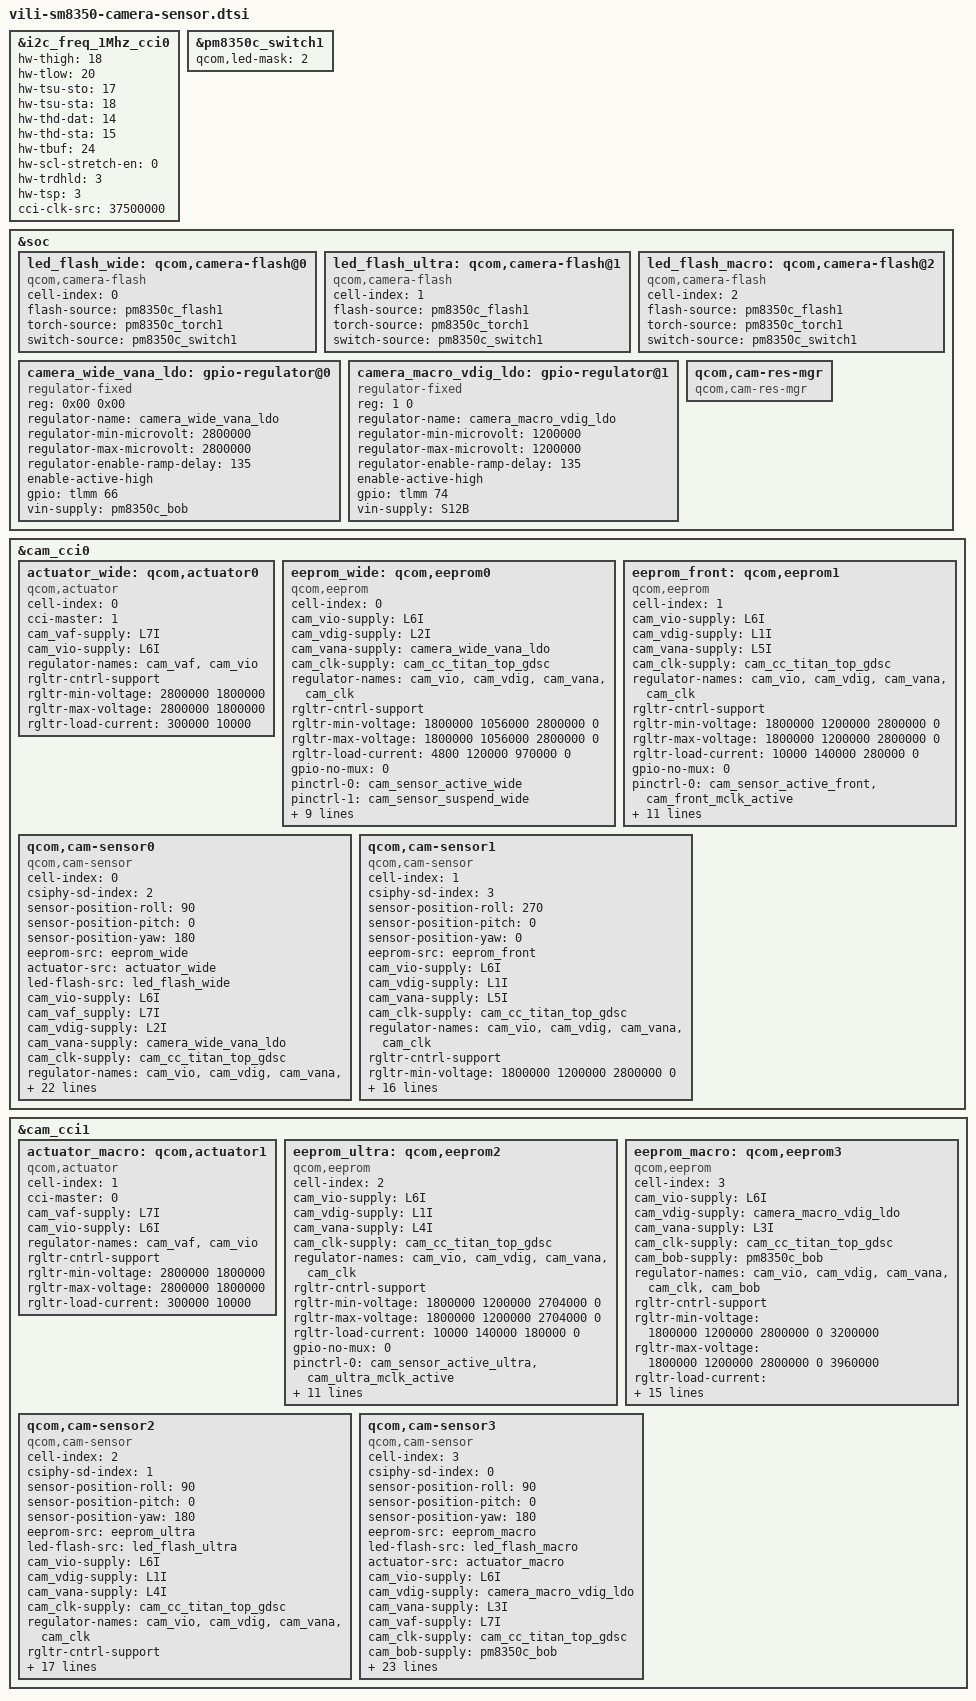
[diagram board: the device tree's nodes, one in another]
#include <dt-bindings/clock/qcom,camcc-lahaina.h>

&i2c_freq_1Mhz_cci0 {
	hw-thigh = <18>;
	hw-tlow = <20>;
	hw-tsu-sto = <17>;
	hw-tsu-sta = <18>;
	hw-thd-dat = <14>;
	hw-thd-sta = <15>;
	hw-tbuf = <24>;
	hw-scl-stretch-en = <0>;
	hw-trdhld = <3>;
	hw-tsp = <3>;
	cci-clk-src = <37500000>;
	status = "ok";
};

&pm8350c_switch1 {
	qcom,led-mask = <2>; /* Channels 2*/
};

&soc {
	led_flash_wide: qcom,camera-flash@0 {
		cell-index = <0>;
		compatible = "qcom,camera-flash";
		flash-source = <&pm8350c_flash1>;
		torch-source = <&pm8350c_torch1>;
		switch-source = <&pm8350c_switch1>;
		status = "ok";
	};

	led_flash_ultra: qcom,camera-flash@1 {
		cell-index = <1>;
		compatible = "qcom,camera-flash";
		flash-source = <&pm8350c_flash1>;
		torch-source = <&pm8350c_torch1>;
		switch-source = <&pm8350c_switch1>;
		status = "ok";
	};

	led_flash_macro: qcom,camera-flash@2 {
		cell-index = <2>;
		compatible = "qcom,camera-flash";
		flash-source = <&pm8350c_flash1>;
		torch-source = <&pm8350c_torch1>;
		switch-source = <&pm8350c_switch1>;
		status = "ok";
	};

	camera_wide_vana_ldo: gpio-regulator@0 {
		compatible = "regulator-fixed";
		reg = <0x00 0x00>;
		regulator-name = "camera_wide_vana_ldo";
		regulator-min-microvolt = <2800000>;
		regulator-max-microvolt = <2800000>;
		regulator-enable-ramp-delay = <135>;
		enable-active-high;
		gpio = <&tlmm 66 0>;
                vin-supply = <&pm8350c_bob>;
	};

	camera_macro_vdig_ldo: gpio-regulator@1 {
		compatible = "regulator-fixed";
		reg = <1 0>;
		regulator-name = "camera_macro_vdig_ldo";
		regulator-min-microvolt = <1200000>;
		regulator-max-microvolt = <1200000>;
		regulator-enable-ramp-delay = <135>;
		enable-active-high;
		gpio = <&tlmm 74 0>;
		vin-supply = <&S12B>;
	};

	qcom,cam-res-mgr {
		compatible = "qcom,cam-res-mgr";
	};
};

&cam_cci0 {
        actuator_wide: qcom,actuator0 {
                cell-index = <0>;
                compatible = "qcom,actuator";
                cci-master = <1>;
                cam_vaf-supply = <&L7I>;
                cam_vio-supply = <&L6I>;
                regulator-names = "cam_vaf", "cam_vio";
                rgltr-cntrl-support;
                rgltr-min-voltage = <2800000 1800000>;
                rgltr-max-voltage = <2800000 1800000>;
                rgltr-load-current = <300000 10000>;
                status = "ok";
        };

	eeprom_wide: qcom,eeprom0 {
		cell-index = <0>;
		compatible = "qcom,eeprom";
		cam_vio-supply = <&L6I>;
		cam_vdig-supply = <&L2I>;
		cam_vana-supply = <&camera_wide_vana_ldo>;
		cam_clk-supply = <&cam_cc_titan_top_gdsc>;
		regulator-names = "cam_vio", "cam_vdig", "cam_vana", "cam_clk";
		rgltr-cntrl-support;
		rgltr-min-voltage = <1800000 1056000 2800000 0>;
		rgltr-max-voltage = <1800000 1056000 2800000 0>;
		rgltr-load-current = <4800 120000 970000 0>;
		gpio-no-mux = <0>;
		pinctrl-names = "cam_default", "cam_suspend";
		pinctrl-0 = <&cam_sensor_active_wide>;
		pinctrl-1 = <&cam_sensor_suspend_wide>;
		gpios = <&tlmm 101 0>,
			<&tlmm 16 0>;
		gpio-reset = <1>;
		gpio-req-tbl-num = <0 1>;
		gpio-req-tbl-flags = <1 0>;
		gpio-req-tbl-label = "CAMIF_MCLK1",
					"CAM_RESET1";
		cci-master = <1>;
		clocks = <&clock_camcc CAM_CC_MCLK1_CLK>;
		clock-names = "cam_clk";
		clock-cntl-level = "nominal";
		clock-rates = <19200000>;
		status = "ok";
	};

	eeprom_front: qcom,eeprom1 {
		cell-index = <1>;
		compatible = "qcom,eeprom";
		cam_vio-supply = <&L6I>;
		cam_vdig-supply = <&L1I>;
		cam_vana-supply = <&L5I>;
		cam_clk-supply = <&cam_cc_titan_top_gdsc>;
		regulator-names = "cam_vio", "cam_vdig", "cam_vana", "cam_clk";
		rgltr-cntrl-support;
		rgltr-min-voltage = <1800000 1200000 2800000 0>;
		rgltr-max-voltage = <1800000 1200000 2800000 0>;
		rgltr-load-current = <10000 140000 280000 0>;
		gpio-no-mux = <0>;
		pinctrl-names = "cam_default", "cam_suspend";
		pinctrl-0 = <&cam_sensor_active_front
			&cam_front_mclk_active>;
		pinctrl-1 = <&cam_sensor_suspend_front
			&cam_front_mclk_suspend>;
		gpios = <&tlmm 100 0>,
			<&tlmm 17 0>;
		gpio-reset = <1>;
		gpio-req-tbl-num = <0 1>;
		gpio-req-tbl-flags = <1 0>;
		gpio-req-tbl-label = "CAMIF_MCLK0",
					"CAM_RESET0";
		cci-master = <0>;
		clocks = <&clock_camcc CAM_CC_MCLK0_CLK>;
		clock-names = "cam_clk";
		clock-cntl-level = "nominal";
		clock-rates = <19200000>;
		status = "ok";
	};

	// wide IMX686 64M AVDD 2.8V
	// wide S5KHM2 108M AVDD 2.9V
	qcom,cam-sensor0 {
		cell-index = <0>;
		compatible = "qcom,cam-sensor";
		csiphy-sd-index = <2>;
		sensor-position-roll = <90>;
		sensor-position-pitch = <0>;
		sensor-position-yaw = <180>;
		eeprom-src = <&eeprom_wide>;
		actuator-src = <&actuator_wide>;
		led-flash-src = <&led_flash_wide>;
		cam_vio-supply = <&L6I>;
		cam_vaf_supply = <&L7I>;
		cam_vdig-supply = <&L2I>;
		cam_vana-supply = <&camera_wide_vana_ldo>;
		cam_clk-supply = <&cam_cc_titan_top_gdsc>;
		regulator-names = "cam_vio", "cam_vdig", "cam_vana", "cam_vaf", "cam_clk";
		rgltr-cntrl-support;
		rgltr-min-voltage = <1800000 1056000 2800000 2800000 0>;
		rgltr-max-voltage = <1800000 1056000 2800000 2800000 0>;
		rgltr-load-current = <10000 140000 280000 280000 0>;
		gpio-no-mux = <0>;
                pinctrl-names = "cam_default", "cam_suspend";
                pinctrl-0 = <&cam_wide_mclk_active
                        &cam_sensor_active_wide>;
                pinctrl-1 = <&cam_wide_mclk_suspend
                        &cam_sensor_suspend_wide>;
		gpios = <&tlmm 101 0>,
			<&tlmm 16 0>;
		gpio-reset = <1>;
		gpio-req-tbl-num = <0 1>;
		gpio-req-tbl-flags = <1 0>;
		gpio-req-tbl-label = "CAMIF_MCLK1",
					"CAM_RESET1";
		cci-master = <1>;
		clocks = <&clock_camcc CAM_CC_MCLK1_CLK>;
		clock-names = "cam_clk";
		clock-cntl-level = "nominal";
		clock-rates = <19200000>;
		status = "ok";
	};

	// Front 20M
	qcom,cam-sensor1 {
		cell-index = <1>;
		compatible = "qcom,cam-sensor";
		csiphy-sd-index = <3>;
		sensor-position-roll = <270>;
		sensor-position-pitch = <0>;
		sensor-position-yaw = <0>;
		eeprom-src = <&eeprom_front>;
		cam_vio-supply = <&L6I>;
		cam_vdig-supply = <&L1I>;
		cam_vana-supply = <&L5I>;
		cam_clk-supply = <&cam_cc_titan_top_gdsc>;
		regulator-names = "cam_vio", "cam_vdig", "cam_vana", "cam_clk";
		rgltr-cntrl-support;
		rgltr-min-voltage = <1800000 1200000 2800000 0>;
		rgltr-max-voltage = <1800000 1200000 2800000 0>;
		rgltr-load-current = <10000 140000 280000 0>;
		gpio-no-mux = <0>;
		pinctrl-names = "cam_default", "cam_suspend";
		pinctrl-0 = <&cam_sensor_active_front
			&cam_front_mclk_active>;
		pinctrl-1 = <&cam_sensor_suspend_front
			&cam_front_mclk_suspend>;
		gpios = <&tlmm 100 0>,
			<&tlmm 17 0>;
		gpio-reset = <1>;
		gpio-req-tbl-num = <0 1>;
		gpio-req-tbl-flags = <1 0>;
		gpio-req-tbl-label = "CAMIF_MCLK0",
					"CAM_RESET0";
		cci-master = <0>;
		clocks = <&clock_camcc CAM_CC_MCLK0_CLK>;
		clock-names = "cam_clk";
		clock-cntl-level = "nominal";
		clock-rates = <19200000>;
		status = "ok";
	};

};

&cam_cci1 {
        actuator_macro: qcom,actuator1 {
                cell-index = <1>;
                compatible = "qcom,actuator";
                cci-master = <0>;
                cam_vaf-supply = <&L7I>;
                cam_vio-supply = <&L6I>;
                regulator-names = "cam_vaf", "cam_vio";
                rgltr-cntrl-support;
                rgltr-min-voltage = <2800000 1800000>;
                rgltr-max-voltage = <2800000 1800000>;
                rgltr-load-current = <300000 10000>;
                status = "ok";
        };

	eeprom_ultra: qcom,eeprom2 {
		cell-index = <2>;
		compatible = "qcom,eeprom";
		cam_vio-supply = <&L6I>;
		cam_vdig-supply = <&L1I>;
		cam_vana-supply = <&L4I>;
		cam_clk-supply = <&cam_cc_titan_top_gdsc>;
		regulator-names = "cam_vio", "cam_vdig", "cam_vana", "cam_clk";
		rgltr-cntrl-support;
		rgltr-min-voltage = <1800000 1200000 2704000 0>;
		rgltr-max-voltage = <1800000 1200000 2704000 0>;
		rgltr-load-current = <10000 140000 180000 0>;
		gpio-no-mux = <0>;
		pinctrl-names = "cam_default", "cam_suspend";
		pinctrl-0 = <&cam_sensor_active_ultra
				&cam_ultra_mclk_active>;
		pinctrl-1 = <&cam_sensor_suspend_ultra
				&cam_ultra_mclk_suspend>;
		gpios = <&tlmm 103 0>,
			<&tlmm 117 0>;
		gpio-reset = <1>;
		gpio-req-tbl-num = <0 1>;
		gpio-req-tbl-flags = <1 0>;
		gpio-req-tbl-label = "CAMIF_MCLK3",
					"CAM_RESET3";
		cci-master = <1>;
		clocks = <&clock_camcc CAM_CC_MCLK3_CLK>;
		clock-names = "cam_clk";
		clock-cntl-level = "nominal";
		clock-rates = <19200000>;
		status = "ok";
	};

	eeprom_macro: qcom,eeprom3 {
		cell-index = <3>;
		compatible = "qcom,eeprom";
		cam_vio-supply = <&L6I>;
		cam_vdig-supply = <&camera_macro_vdig_ldo>;
		cam_vana-supply = <&L3I>;
		cam_clk-supply = <&cam_cc_titan_top_gdsc>;
		cam_bob-supply = <&pm8350c_bob>;
		regulator-names = "cam_vio", "cam_vdig", "cam_vana"
			          , "cam_clk", "cam_bob";
		rgltr-cntrl-support;
		rgltr-min-voltage = <1800000 1200000 2800000 0 3200000>;
		rgltr-max-voltage = <1800000 1200000 2800000 0 3960000>;
		rgltr-load-current = <10000 140000 180000 0 2000000>;
		gpio-no-mux = <0>;
		pinctrl-names = "cam_default", "cam_suspend";
		pinctrl-0 = <&cam_sensor_active_macro
				&cam_macro_mclk_active>;
		pinctrl-1 = <&cam_sensor_suspend_macro
				&cam_macro_mclk_suspend>;
		gpios = <&tlmm 102 0>,
			<&tlmm 106 0>;
		gpio-reset = <1>;
		gpio-req-tbl-num = <0 1>;
		gpio-req-tbl-flags = <1 0>;
		gpio-req-tbl-label = "CAMIF_MCLK2",
					"CAM_RESET2";
		cci-master = <0>;
		clocks = <&clock_camcc CAM_CC_MCLK2_CLK>;
		clock-names = "cam_clk";
		clock-cntl-level = "nominal";
		clock-rates = <19200000>;
		status = "ok";
	};

	// Ultra 8M
	qcom,cam-sensor2 {
		cell-index = <2>;
		compatible = "qcom,cam-sensor";
		csiphy-sd-index = <1>;
		sensor-position-roll = <90>;
		sensor-position-pitch = <0>;
		sensor-position-yaw = <180>;
		eeprom-src = <&eeprom_ultra>;
		//actuator-src = <&actuator_ultra>;
		led-flash-src = <&led_flash_ultra>;
		cam_vio-supply = <&L6I>;
		cam_vdig-supply = <&L1I>;
		cam_vana-supply = <&L4I>;
		cam_clk-supply = <&cam_cc_titan_top_gdsc>;
		regulator-names = "cam_vio", "cam_vdig", "cam_vana", "cam_clk";
		rgltr-cntrl-support;
		rgltr-min-voltage = <1800000 1200000 2704000 0>;
		rgltr-max-voltage = <1800000 1200000 2704000 0>;
		rgltr-load-current = <10000 140000 180000 0>;
		gpio-no-mux = <0>;
		pinctrl-names = "cam_default", "cam_suspend";
		pinctrl-0 = <&cam_sensor_active_ultra
				&cam_ultra_mclk_active>;
		pinctrl-1 = <&cam_sensor_suspend_ultra
				&cam_ultra_mclk_suspend>;
		gpios = <&tlmm 103 0>,
			<&tlmm 117 0>;
		gpio-reset = <1>;
		gpio-req-tbl-num = <0 1>;
		gpio-req-tbl-flags = <1 0>;
		gpio-req-tbl-label = "CAMIF_MCLK3",
					"CAM_RESET3";
		cci-master = <1>;
		clocks = <&clock_camcc CAM_CC_MCLK3_CLK>;
		clock-names = "cam_clk";
		clock-cntl-level = "nominal";
		clock-rates = <19200000>;
		status = "ok";
	};

	// Folded 5M MACRO
	qcom,cam-sensor3 {
		cell-index = <3>;
		compatible = "qcom,cam-sensor";
		csiphy-sd-index = <0>;
		sensor-position-roll = <90>;
		sensor-position-pitch = <0>;
		sensor-position-yaw = <180>;
		eeprom-src = <&eeprom_macro>;
		led-flash-src = <&led_flash_macro>;
		actuator-src = <&actuator_macro>;
		cam_vio-supply = <&L6I>;
		cam_vdig-supply = <&camera_macro_vdig_ldo>;
		cam_vana-supply = <&L3I>;
		cam_vaf-supply = <&L7I>;
		cam_clk-supply = <&cam_cc_titan_top_gdsc>;
		cam_bob-supply = <&pm8350c_bob>;
		regulator-names = "cam_vio", "cam_vdig", "cam_vana", "cam_vaf"
			          , "cam_clk", "cam_bob";
		rgltr-cntrl-support;
		rgltr-min-voltage = <1800000 1200000 2800000 2800000 0 3200000>;
		rgltr-max-voltage = <1800000 1200000 2800000 2800000 0 3960000>;
		rgltr-load-current = <10000 140000 180000 296000 0 2000000>;
		gpio-no-mux = <0>;
		pinctrl-names = "cam_default", "cam_suspend";
		pinctrl-0 = <&cam_sensor_active_macro
				&cam_macro_mclk_active>;
		pinctrl-1 = <&cam_sensor_suspend_macro
				&cam_macro_mclk_suspend>;
		gpios = <&tlmm 102 0>,
			<&tlmm 106 0>;
		gpio-reset = <1>;
		gpio-req-tbl-num = <0 1>;
		gpio-req-tbl-flags = <1 0>;
		gpio-req-tbl-label = "CAMIF_MCLK2",
					"CAM_RESET2";
		cci-master = <0>;
		clocks = <&clock_camcc CAM_CC_MCLK2_CLK>;
		clock-names = "cam_clk";
		clock-cntl-level = "nominal";
		clock-rates = <19200000>;
		status = "ok";
	};
};
